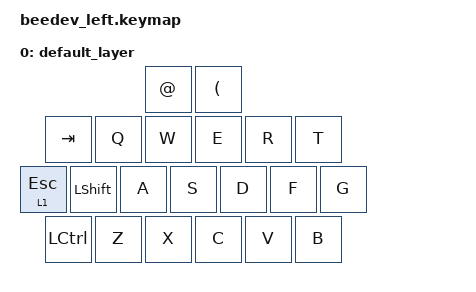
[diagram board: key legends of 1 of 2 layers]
#include <behaviors.dtsi>
#include <dt-bindings/zmk/bt.h>
#include <dt-bindings/zmk/keys.h>
#include <dt-bindings/zmk/outputs.h>

/ {
        keymap {
        compatible = "zmk,keymap";

        default_layer {
            bindings = <
                                                        &kp AT   &kp LEFT_PARENTHESIS                  
                                    &kp TAB     &kp Q   &kp W    &kp E                  &kp R   &kp T    
                &lt 1 ESC &kp LSHIFT  &kp A   &kp S    &kp D                  &kp F   &kp G    
                                    &kp LCTRL   &kp Z   &kp X    &kp C                  &kp V   &kp B    
            >;
        };
        
        admin_layer {
            bindings = <
                                                        &sys_reset      &bootloader                        
                       &bt_select 0    &bt_select 1     &bt_select 2    &bt_select 3    &bt_select 4        
                       &bt_pair        &bt_clear_bonds                                                  
                                                                                                      
            >;
        };
    };
};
